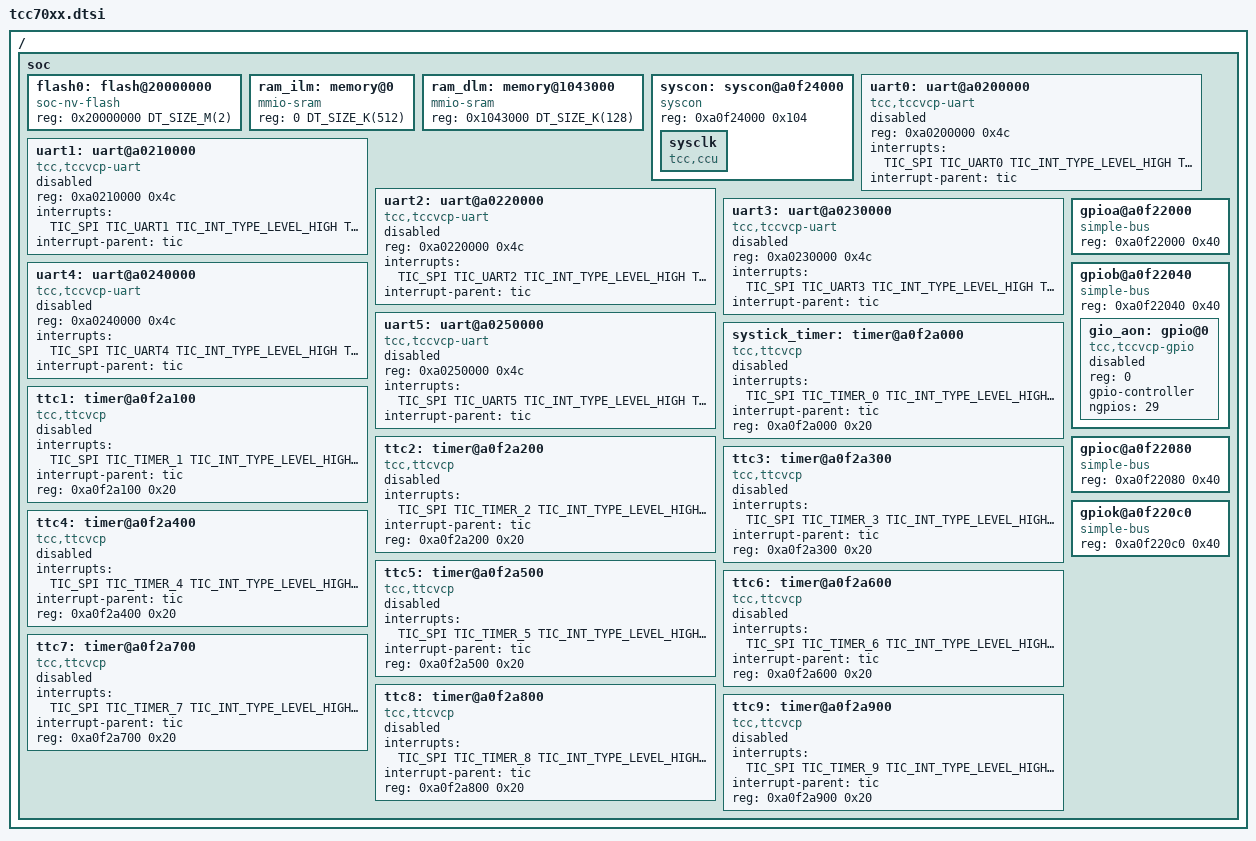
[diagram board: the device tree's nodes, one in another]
/*
 * Copyright 2024 Hounjoung Rim <hounjoung@tsnlab.com>
 *
 * SPDX-License-Identifier: Apache-2.0
 */

#include <mem.h>
#include <freq.h>
#include <arm/armv7-r.dtsi>
#include <zephyr/dt-bindings/interrupt-controller/tcc-tic.h>

/ {
	soc {
		flash0: flash@20000000 {
			compatible = "soc-nv-flash";
			reg = <0x20000000 DT_SIZE_M(2)>;
		};

		ram_ilm: memory@0 {
			compatible = "mmio-sram";
			reg = <0 DT_SIZE_K(512)>;
		};

		ram_dlm: memory@1043000 {
			compatible = "mmio-sram";
			reg = <0x1043000 DT_SIZE_K(128)>;
		};

		syscon: syscon@a0f24000 {
			compatible = "syscon";
			reg = <0xa0f24000 0x104>;

			sysclk: sysclk {
				compatible = "tcc,ccu";
				#clock-cells = <1>;
			};
		};

		uart0: uart@a0200000 {
			compatible = "tcc,tccvcp-uart";
			reg = <0xa0200000 0x4c>;
			status = "disabled";
			interrupts = <TIC_SPI TIC_UART0 TIC_INT_TYPE_LEVEL_HIGH
						TIC_IRQ_DEFAULT_PRIORITY>;
			interrupt-names = "irq_uart0";
			interrupt-parent = <&tic>;
		};

		uart1: uart@a0210000 {
			compatible = "tcc,tccvcp-uart";
			reg = <0xa0210000 0x4c>;
			status = "disabled";
			interrupts = <TIC_SPI TIC_UART1 TIC_INT_TYPE_LEVEL_HIGH
						TIC_IRQ_DEFAULT_PRIORITY>;
			interrupt-names = "irq_uart1";
			interrupt-parent = <&tic>;
		};

		uart2: uart@a0220000 {
			compatible = "tcc,tccvcp-uart";
			reg = <0xa0220000 0x4c>;
			status = "disabled";
			interrupts = <TIC_SPI TIC_UART2 TIC_INT_TYPE_LEVEL_HIGH
						TIC_IRQ_DEFAULT_PRIORITY>;
			interrupt-names = "irq_uart2";
			interrupt-parent = <&tic>;
		};

		uart3: uart@a0230000 {
			compatible = "tcc,tccvcp-uart";
			reg = <0xa0230000 0x4c>;
			status = "disabled";
			interrupts = <TIC_SPI TIC_UART3 TIC_INT_TYPE_LEVEL_HIGH
						TIC_IRQ_DEFAULT_PRIORITY>;
			interrupt-names = "irq_uart3";
			interrupt-parent = <&tic>;
		};

		uart4: uart@a0240000 {
			compatible = "tcc,tccvcp-uart";
			reg = <0xa0240000 0x4c>;
			status = "disabled";
			interrupts = <TIC_SPI TIC_UART4 TIC_INT_TYPE_LEVEL_HIGH
						TIC_IRQ_DEFAULT_PRIORITY>;
			interrupt-names = "irq_uart4";
			interrupt-parent = <&tic>;
		};

		uart5: uart@a0250000 {
			compatible = "tcc,tccvcp-uart";
			reg = <0xa0250000 0x4c>;
			status = "disabled";
			interrupts = <TIC_SPI TIC_UART5 TIC_INT_TYPE_LEVEL_HIGH
						TIC_IRQ_DEFAULT_PRIORITY>;
			interrupt-names = "irq_uart5";
			interrupt-parent = <&tic>;
		};

		systick_timer: timer@a0f2a000 {
			compatible = "tcc,ttcvcp";
			status = "disabled";
			interrupts = <TIC_SPI TIC_TIMER_0 TIC_INT_TYPE_LEVEL_HIGH
						TIC_IRQ_DEFAULT_PRIORITY>;
			interrupt-names = "irq_timer0";
			interrupt-parent = <&tic>;
			reg = <0xa0f2a000 0x20>;
		};

		ttc1: timer@a0f2a100 {
			compatible = "tcc,ttcvcp";
			status = "disabled";
			interrupts = <TIC_SPI TIC_TIMER_1 TIC_INT_TYPE_LEVEL_HIGH
						TIC_IRQ_DEFAULT_PRIORITY>;
			interrupt-names = "irq_timer1";
			interrupt-parent = <&tic>;
			reg = <0xa0f2a100 0x20>;
		};

		ttc2: timer@a0f2a200 {
			compatible = "tcc,ttcvcp";
			status = "disabled";
			interrupts = <TIC_SPI TIC_TIMER_2 TIC_INT_TYPE_LEVEL_HIGH
						TIC_IRQ_DEFAULT_PRIORITY>;
			interrupt-names = "irq_timer2";
			interrupt-parent = <&tic>;
			reg = <0xa0f2a200 0x20>;
		};

		ttc3: timer@a0f2a300 {
			compatible = "tcc,ttcvcp";
			status = "disabled";
			interrupts = <TIC_SPI TIC_TIMER_3 TIC_INT_TYPE_LEVEL_HIGH
						TIC_IRQ_DEFAULT_PRIORITY>;
			interrupt-names = "irq_timer3";
			interrupt-parent = <&tic>;
			reg = <0xa0f2a300 0x20>;
		};

		ttc4: timer@a0f2a400 {
			compatible = "tcc,ttcvcp";
			status = "disabled";
			interrupts = <TIC_SPI TIC_TIMER_4 TIC_INT_TYPE_LEVEL_HIGH
						TIC_IRQ_DEFAULT_PRIORITY>;
			interrupt-names = "irq_timer4";
			interrupt-parent = <&tic>;
			reg = <0xa0f2a400 0x20>;
		};

		ttc5: timer@a0f2a500 {
			compatible = "tcc,ttcvcp";
			status = "disabled";
			interrupts = <TIC_SPI TIC_TIMER_5 TIC_INT_TYPE_LEVEL_HIGH
						TIC_IRQ_DEFAULT_PRIORITY>;
			interrupt-names = "irq_timer5";
			interrupt-parent = <&tic>;
			reg = <0xa0f2a500 0x20>;
		};

		ttc6: timer@a0f2a600 {
			compatible = "tcc,ttcvcp";
			status = "disabled";
			interrupts = <TIC_SPI TIC_TIMER_6 TIC_INT_TYPE_LEVEL_HIGH
						TIC_IRQ_DEFAULT_PRIORITY>;
			interrupt-names = "irq_timer6";
			interrupt-parent = <&tic>;
			reg = <0xa0f2a600 0x20>;
		};

		ttc7: timer@a0f2a700 {
			compatible = "tcc,ttcvcp";
			status = "disabled";
			interrupts = <TIC_SPI TIC_TIMER_7 TIC_INT_TYPE_LEVEL_HIGH
						TIC_IRQ_DEFAULT_PRIORITY>;
			interrupt-names = "irq_timer7";
			interrupt-parent = <&tic>;
			reg = <0xa0f2a700 0x20>;
		};

		ttc8: timer@a0f2a800 {
			compatible = "tcc,ttcvcp";
			status = "disabled";
			interrupts = <TIC_SPI TIC_TIMER_8 TIC_INT_TYPE_LEVEL_HIGH
						TIC_IRQ_DEFAULT_PRIORITY>;
			interrupt-names = "irq_timer8";
			interrupt-parent = <&tic>;
			reg = <0xa0f2a800 0x20>;
		};

		ttc9: timer@a0f2a900 {
			compatible = "tcc,ttcvcp";
			status = "disabled";
			interrupts = <TIC_SPI TIC_TIMER_9 TIC_INT_TYPE_LEVEL_HIGH
						TIC_IRQ_DEFAULT_PRIORITY>;
			interrupt-names = "irq_timer9";
			interrupt-parent = <&tic>;
			reg = <0xa0f2a900 0x20>;
		};

		gpioa@a0f22000 {
			compatible = "simple-bus";
			reg = <0xa0f22000 0x40>;

			#address-cells = <1>;
			#size-cells = <0>;
		};

		gpiob@a0f22040 {
			compatible = "simple-bus";
			reg = <0xa0f22040 0x40>;

			#address-cells = <1>;
			#size-cells = <0>;

			gio_aon: gpio@0 {
				compatible = "tcc,tccvcp-gpio";
				reg = <0>;
				gpio-controller;
				#gpio-cells = <2>;
				ngpios = <29>;
				status = "disabled";
			};
		};

		gpioc@a0f22080 {
			compatible = "simple-bus";
			reg = <0xa0f22080 0x40>;

			#address-cells = <1>;
			#size-cells = <0>;
		};

		gpiok@a0f220c0 {
			compatible = "simple-bus";
			reg = <0xa0f220c0 0x40>;

			#address-cells = <1>;
			#size-cells = <0>;
		};
	};
};
